# NSS_0_CFG_MDIO register map
Vendor: Texas Instruments
Peripheral module from a debugger description file (folder 66AK2G0x_66AK2G1x).
Registers are 32-bit, access per field, reset 0x0 unless marked. A register's access mark holds for its fields unless they carry their own. Offsets are as the file gives them; lines under a group give offsets from that group; [hi:lo] are bit positions; {n}, {i} and the like mark numbered series; 'fields as' and 'values as' point back to an identical list; <NAME> marks a mode.

## NSS_0_CFG_MDIO
0x00 MDIO_VERSION ro reset 0x70105
  [31:0] REV — TI internal data. Identifies revision of peripheral.
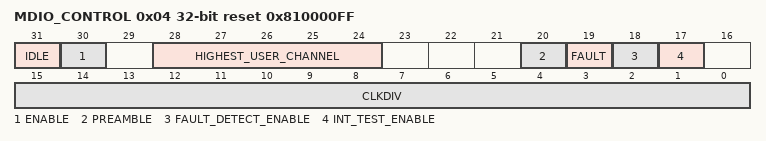
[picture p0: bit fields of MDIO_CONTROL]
0x04 MDIO_CONTROL reset 0x810000FF
  [31] IDLE ro — MDIO state machine idle indicator. 0: State machine is running. 1: State machine is in idle state.
  [30] ENABLE rw — Enable control. If the MDIO state machine is active at the time it is disabled, it will complete the current operation before halting and setting the IDLE bit. If using byte access, the ENABLE bit has to be the last bit written in this register. 0: Disables the MDIO state machine. 1: Enable the MDIO state machine.
  [28:24] HIGHEST_USER_CHANNEL ro — Highest user channel. This field specifies the highest user access channel that is available in the module. E.g. 0 = channel 0 only. 1 = channels 0 and 1, and so on. The device itself may not pin out all channels. See Environment section for details.
  [20] PREAMBLE rw — Preamble disable. 0: Standard MDIO preamble is used. 1: Disables this device from sending MDIO frame preambles.
  [19] FAULT rw — Fault indicator. This bit is set to 1 if the MDIO pins fail to read back what the device is driving onto them. This indicates a physical layer fault and the module state machine is reset. Writing a 1 to it clears this bit. 0: No failure. 1: Physical layer fault; the MDIO state machine is reset.
  [18] FAULT_DETECT_ENABLE rw — Fault detect enable. This bit has to be set to 1 to enable the physical layer fault detection. 0: Disables the physical layer fault detection. 1: Enables the physical layer fault detection.
  [17] INT_TEST_ENABLE rw — Interrupt test enable. This bit can be set to 1 to enable the host to set the USERINT and LINKINT bits for test purposes. 0: Interrupt bits are not set. 1: Enables the host to set the USERINT and LINKINT bits for test purposes.
  [15:0] CLKDIV rw — Clock divider. This field specifies the division ratio between ICLK and the frequency of MDCLK. MDCLK is disabled when CLKDIV is set to 0. MDCLK frequency = ICLK frequency/(CLKDIV+1).
0x08 MDIO_ALIVE rw
  [31:0] ALIVE — MDIO alive. Bit is set if the most recent access to the PHY was acknowledged by the PHY, the bit is reset if the PHY fails to acknowledge the access. Both the user and polling accesses to a PHY will cause the corresponding ALIVE bit to be updated. The ALIVE bits are only meant to be used to give an indication of the presence or not of a PHY with the corresponding address. Writing a 1 to any bit will clear it, writing a 0 has no effect.
0x0C MDIO_LINK ro
  [31:0] LINK — MDIO link state. This register is updated after a read of the Generic Status Register of a PHY. The bit is set if the PHY has link and the PHY acknowledges the read transaction. The bit is reset if the PHY indicates it does not have link or fails to acknowledge the read transaction. Writes to the register have no effect.
0x10 MDIO_LINK_INT_RAW
  [1:0] LINKINTRAW rw — MDIO link change event raw value. Channels 1:0
0x14 MDIO_LINK_INT_MASKED
  [1:0] LINKINTMASKED rw — MDIO link change interrupt, masked value. When asserted 1, a bit indicates that there was an MDIO link change event (i.e. change in the MDIO Link register) corresponding to the PHY address in the MDIO_USERPHYSEL register and the LINKINTENB bit was set. LINKINTMASKED[0] corresponds to MDIO_USERPHYSEL0. Writing a 1 will clear the interrupt and writing 0 has no effect. If the INTTESTENB bit in theMDIO_CONTROL register is set, the host may set the LINKINT bits to a 1. This mode may be used for test purposes.
0x20 MDIO_USER_INT_RAW
  [1:0] USERINTRAW rw — Raw value of MDIO user command complete event for the MDIO_USERACCESS register. When asserted 1, a bit indicates that the previously scheduled PHY read or write command using that MDIO_USERACCESS register has completed. Writing a 1 will clear the event and writing 0 has no effect. If the INTTESTENB bit in theMDIO_CONTROL register is set, the host may set the USERINTRAW bits to a 1. This mode may be used for test purposes.
0x24 MDIO_USER_INT_MASKED
  [1:0] USERINTMASKED rw — Masked value of MDIO user command complete interrupt for the MDIO_USERACCESS register. When asserted 1, a bit indicates that the previously scheduled PHY read or write command using MDIO_USERACCESS register has completed and the corresponding USERINTMASKSET bit is set to 1. Writing a 1 will clear the interrupt and writing 0 has no effect. If the INTTESTENB bit in theMDIO_CONTROL register is set, the host may set the USERINTMASKED bits to a 1. This mode may be used for test purposes.
0x28 MDIO_USER_INT_MASK_SET
  [1:0] USERINTMASKSET rw — MDIO user interrupt mask set for USERINTMASKED. Writing a bit to 1 will enable MDIO user command complete interrupts for MDIO_USERACCESS register. MDIO user interrupt for MDIO_USERACCESS register is disabled if the bit is 0. Writing a 0 to this register has no effect.
0x2C MDIO_USER_INT_MASK_CLEAR
  [1:0] USERINTMASKCLR rw — MDIO user command complete interrupt mask clear for USERINTMASKED. Writing a bit to 1 will disable further user command complete interrupts for MDIO_USERACCESS register. Writing a 0 to this register has no effect.
